# AT32F403xx_v2 register map
Vendor: Keil; Series: AT32F403; File version: 1.0
CPU: CM4 r0p1, little endian, no MPU, FPU, 4 interrupt priority bits
Registers are 32-bit, read-write, reset 0x0 unless marked. A register's access mark holds for its fields unless they carry their own. Offsets are from the block's base; [hi:lo] are bit positions; {n}, {i} and the like mark numbered series.

## PWC — Power control
Base 0x40007000
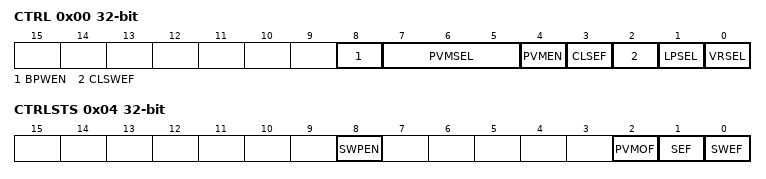
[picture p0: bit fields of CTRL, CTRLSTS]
0x00 CTRL — Power control register (PWC_CTRL)
  [8] BPWEN — Battery powered domain write enable
  [7:5] PVMSEL — Power voltage monitoring boundary select
  [4] PVMEN — Power voltage monitoring enable
  [3] CLSEF — Clear SEF flag
  [2] CLSWEF — Clear SWEF flag
  [1] LPSEL — Low power mode select when Cortex-M4F sleepdeep
  [0] VRSEL — Voltage regulator state select when deepsleep mode
0x04 CTRLSTS — Power control and status register (PWC_CTRLSTS)
  [8] SWPEN — Standby wake-up pin enable
  [2] PVMOF ro — Power voltage monitoring output flag
  [1] SEF ro — Standby mode entry flag
  [0] SWEF ro — Standby wake-up event flag

## GPIOA — General purpose IO
Base 0x40010800
Same registers: GPIOB 0x40010C00, GPIOC 0x40011000, GPIOD 0x40011400, GPIOE 0x40011800, GPIOF 0x40011C00, GPIOG 0x40012000
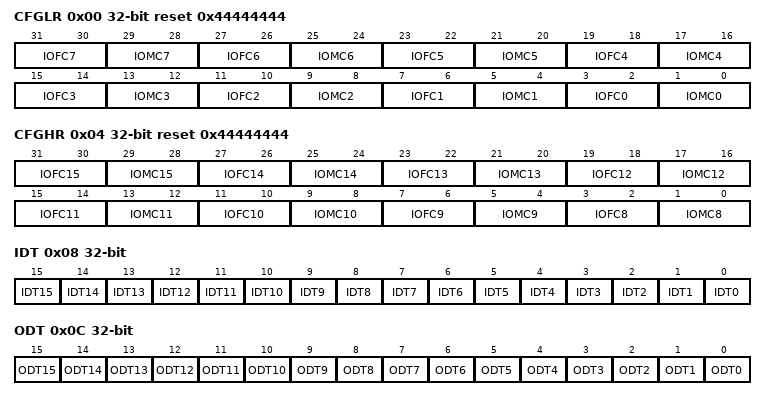
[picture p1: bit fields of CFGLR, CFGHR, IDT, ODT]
0x00 CFGLR reset 0x44444444 — GPIO function configurate low register
  [31:30] IOFC7 — Port n.7 function configurate bits
  [29:28] IOMC7 — Port n.7 mode configurate bits
  [27:26] IOFC6 — Port n.6 function configurate bits
  [25:24] IOMC6 — Port n.6 mode configurate bits
  [23:22] IOFC5 — Port n.5 function configurate bits
  [21:20] IOMC5 — Port n.5 mode configurate bits
  [19:18] IOFC4 — Port n.4 function configurate bits
  [17:16] IOMC4 — Port n.4 mode configurate bits
  [15:14] IOFC3 — Port n.3 function configurate bits
  [13:12] IOMC3 — Port n.3 mode configurate bits
  [11:10] IOFC2 — Port n.2 function configurate bits
  [9:8] IOMC2 — Port n.2 mode configurate bits
  [7:6] IOFC1 — Port n.1 function configurate bits
  [5:4] IOMC1 — Port n.1 mode configurate bits
  [3:2] IOFC0 — Port n.0 function configurate bits
  [1:0] IOMC0 — Port n.0 mode configurate bits
0x04 CFGHR reset 0x44444444 — GPIO function configurate high register
  [31:30] IOFC15 — Port n.15 function configurate bits
  [29:28] IOMC15 — Port n.15 mode configurate bits
  [27:26] IOFC14 — Port n.14 function configurate bits
  [25:24] IOMC14 — Port n.14 mode configurate bits
  [23:22] IOFC13 — Port n.13 function configurate bits
  [21:20] IOMC13 — Port n.13 mode configurate bits
  [19:18] IOFC12 — Port n.12 function configurate bits
  [17:16] IOMC12 — Port n.12 mode configurate bits
  [15:14] IOFC11 — Port n.11 function configurate bits
  [13:12] IOMC11 — Port n.11 mode configurate bits
  [11:10] IOFC10 — Port n.10 function configurate bits
  [9:8] IOMC10 — Port n.10 mode configurate bits
  [7:6] IOFC9 — Port n.9 function configurate bits
  [5:4] IOMC9 — Port n.9 mode configurate bits
  [3:2] IOFC8 — Port n.8 function configurate bits
  [1:0] IOMC8 — Port n.8 mode configurate bits
0x08 IDT ro — Port input data register
  [n] IDT{n} (n=0..15) — Port input data
0x0C ODT — Port output data register
  [n] ODT{n} (n=0..15) — Port output data
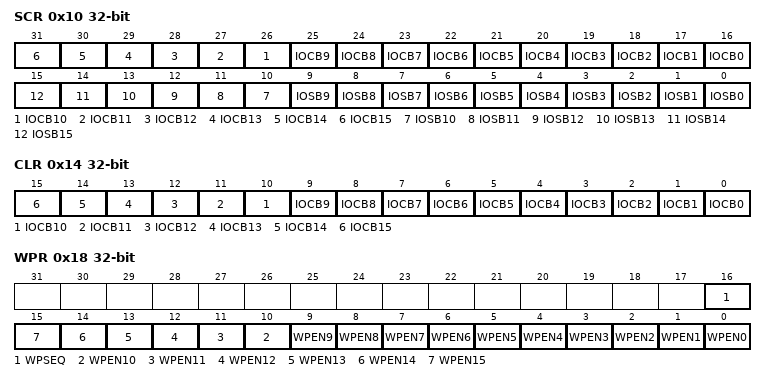
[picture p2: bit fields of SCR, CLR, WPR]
0x10 SCR — Port bit set/clear register
  [n+16] IOCB{n} (n=0..15) — Clear bit {n}
  [n] IOSB{n} (n=3..15) — Set bit {n}
  [2] IOSB2 — Set bit 1
  [1] IOSB1 — Set bit 1
  [0] IOSB0 — Set bit 0
0x14 CLR — Port bit reset register
  [n] IOCB{n} (n=3..15) — Clear bit {n}
  [2] IOCB2 — Clear bit 1
  [1] IOCB1 — Clear bit 1
  [0] IOCB0 — Clear bit 0
0x18 WPR — Port write protect register
  [16] WPSEQ — Write protect sequence
  [n] WPEN{n} (n=0..15) — Write protect enable {n}

## IOMUX — IO MUX function
Base 0x40010000
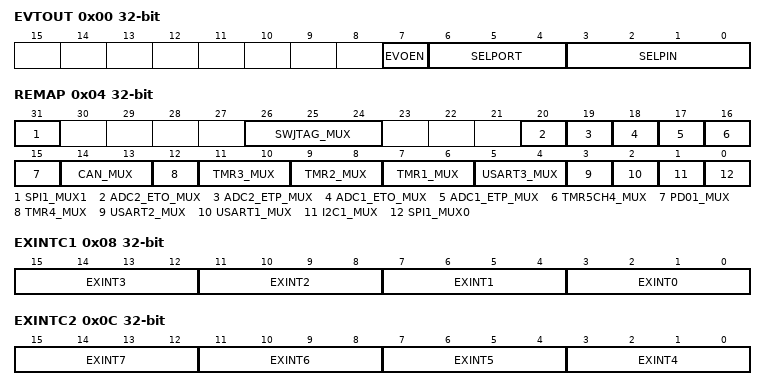
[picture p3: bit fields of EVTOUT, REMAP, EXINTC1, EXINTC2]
0x00 EVTOUT — Event output register (IOMUX_EVTOUT)
  [7] EVOEN — Event output enable
  [6:4] SELPORT — Select port
  [3:0] SELPIN — Select pin
0x04 REMAP — IO MUX remap register (IOMUX_REMAP)
  [31] SPI1_MUX1 — SPI1 muxing bit1
  [26:24] SWJTAG_MUX — SWD JTAG muxing
  [20] ADC2_ETO_MUX — ADC2 external trigger ordinary conversion muxing
  [19] ADC2_ETP_MUX — ADC2 external trigger preempted conversion muxing
  [18] ADC1_ETO_MUX — ADC1 external trigger ordinary conversion muxing
  [17] ADC1_ETP_MUX — ADC1 external trigger preempted conversion muxing
  [16] TMR5CH4_MUX — TMR5 channel4 internal muxing
  [15] PD01_MUX — PD0/PD1 muxing on OSCIN/OSCOUT
  [14:13] CAN_MUX — CAN1 muxing
  [12] TMR4_MUX — TMR4 muxing
  [11:10] TMR3_MUX — TMR3 muxing
  [9:8] TMR2_MUX — TMR2 muxing
  [7:6] TMR1_MUX — TMR1 muxing
  [5:4] USART3_MUX — USART3 muxing
  [3] USART2_MUX — USART2 muxing
  [2] USART1_MUX — USART1 muxing
  [1] I2C1_MUX — I2C1 muxing
  [0] SPI1_MUX0 — SPI1 muxing bit0
0x08 EXINTC1 — External interrupt configuration register 1 (IOMUX_EXINTC1)
  [4n+3:4n] EXINT{n} (n=0..3) — Configure EXINT{n} source
0x0C EXINTC2 — External interrupt configuration register 2 (IOMUX_EXINTC2)
  [4n-13:4n-16] EXINT{n} (n=4..7) — Configure EXINT{n} source
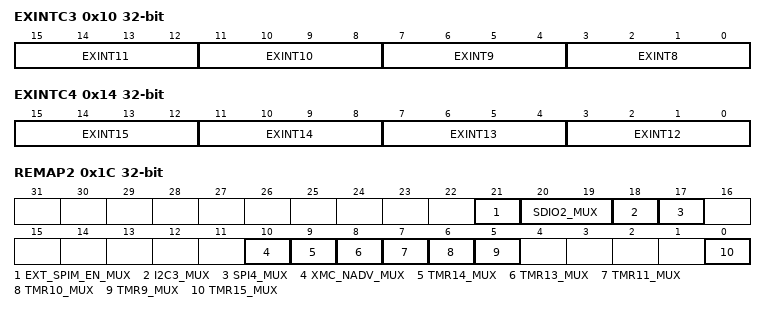
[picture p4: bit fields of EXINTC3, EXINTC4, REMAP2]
0x10 EXINTC3 — External interrupt configuration register 3 (IOMUX_EXINTC3)
  [4n-29:4n-32] EXINT{n} (n=8..11) — Configure EXINT{n} source
0x14 EXINTC4 — External interrupt configuration register 4 (IOMUX_EXINTC4)
  [4n-45:4n-48] EXINT{n} (n=12..15) — Configure EXINT{n} source
0x1C REMAP2 — IO MUX remap register 2 (IOMUX_REMAP2)
  [21] EXT_SPIM_EN_MUX — SPIM enable muxing
  [20:19] SDIO2_MUX — SDIO2 muxing
  [18] I2C3_MUX — I2C3 muxing
  [17] SPI4_MUX — SPI4 muxing
  [10] XMC_NADV_MUX — NADV connect/disconnect
  [9] TMR14_MUX — TMR14 muxing
  [8] TMR13_MUX — TMR13 muxing
  [7] TMR11_MUX — TMR11 muxing
  [6] TMR10_MUX — TMR10 muxing
  [5] TMR9_MUX — TMR9 muxing
  [0] TMR15_MUX — TMR15 muxing
